# CONTROLSS_DAC0_CONTROLSS_DAC0 register map
Vendor: Texas Instruments
Peripheral module from a debugger description file (folder AM263).
Registers are 16-bit, read-write, reset 0x0 unless marked. A register's access mark holds for its fields unless they carry their own. Offsets are as the file gives them; lines under a group give offsets from that group; [hi:lo] are bit positions; {n}, {i} and the like mark numbered series; 'fields as' and 'values as' point back to an identical list; <NAME> marks a mode.

## CONTROLSS_DAC0_CONTROLSS_DAC0
0x00 CONTROLSS_DAC0_DACREV ro
  [7:0] REV — DAC Revision
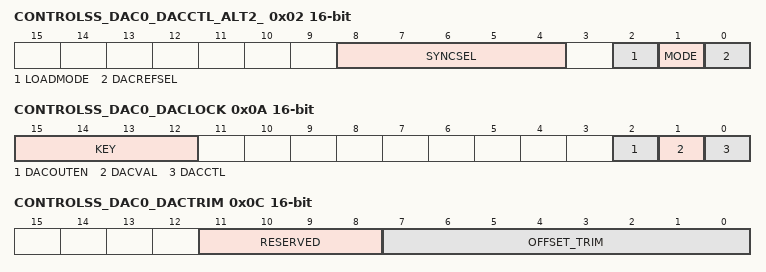
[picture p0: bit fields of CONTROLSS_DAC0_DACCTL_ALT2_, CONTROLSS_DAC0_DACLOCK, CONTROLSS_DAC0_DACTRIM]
0x02 CONTROLSS_DAC0_DACCTL_ALT2_
  [8:4] SYNCSEL — DAC EPWMSYNCPER select. Determines which EPWMSYNCPER signal will update the DACVALA register. Where n represents the maximum number of EPWMSYNCPER signals available on the device: 0 EPWM1SYNCPER 1 EPWM2SYNCPER 2 EPWM3SYNCPER ... n-1 EPWMnSYNCPER
  [2] LOADMODE — DACVALA load mode. Determines when the DACVALA register is updated with the value from DACVALS. 0 Load on next SYSCLK 1 Load on next EPWMSYNCPER specified by SYNCSEL
  [1] MODE — DAC gain mode select. Selects the gain mode for the buffered output. The MODE value is only used when DACREFSEL=1 and internal ADC reference mode is selected. 0 Gain is 1 1 Gain is 2
  [0] DACREFSEL — DAC reference select. Selects which voltage references are used by the DAC. 0 VDAC/VSSA are the reference voltages 1 ADC VREFHI/VSSA are the reference voltages
0x04 CONTROLSS_DAC0_DACVALA ro
  [11:0] DACVALA — Active output code currently driven by the DAC
0x06 CONTROLSS_DAC0_DACVALS
  [11:0] DACVALS — Shadow output code to be loaded into DACVALA
0x08 CONTROLSS_DAC0_DACOUTEN
  [0] DACOUTEN — DAC output enable 0 DAC output is disabled 1 DAC output is enabled
0x0A CONTROLSS_DAC0_DACLOCK access not given
  [15:12] KEY — Writes to this register succeed only if this field is written with a value of 0xA. Only 16-bit writes will succeed (provided the KEY matches). Read-modify-writes to individual bits in this register will be ignored. (access RW RRETURNS0S)
  [2] DACOUTEN — Lock write-access to the DACOUTEN register. 0 DACOUTEN register is not locked. Write 0 to this bit has no effect. 1 DACOUTEN register is locked. Only a system reset can clear this bit. (access RW SONCE)
  [1] DACVAL — Lock write-access to the DACVALS register. 0 DACVALS register is not locked. Write 0 to this bit has no effect. 1 DACVALS register is locked. Only a system reset can clear this bit. (access RW SONCE)
  [0] DACCTL — Lock write-access to the DACCTL register. 0 DACCTL register is not locked. Write 0 to this bit has no effect. 1 DACCTL register is locked. Only a system reset can clear this bit. (access RW SONCE)
0x0C CONTROLSS_DAC0_DACTRIM
  [11:8] RESERVED — DAC Gain Trim. This signed (two's complement) bit field is used to adjust the gain of the DAC. This register will be written with a factory set value during the device boot procedure. 1000 Gain is increased by the equivalent of 0.8% ... 1110 Gain is increased by the equivalent of 0.2% LSB 1111 Gain is increased by the equivalent of 0.1% LSB 0000 Gain is not adjusted 0001 Gain is decreased by the equivalent of 0.1% LSB 0010 Gain is decreased by the equivalent of 0.2% LSB ... 0111 Gain is decreased by the equivalent of 0.7% LSB
  [7:0] OFFSET_TRIM — DAC Offset Trim. This register should not be modified unless specifically indicated by TI Errata or other documentation. Modifying the contents of this register could cause this module to operate outside of datasheet specifications.
